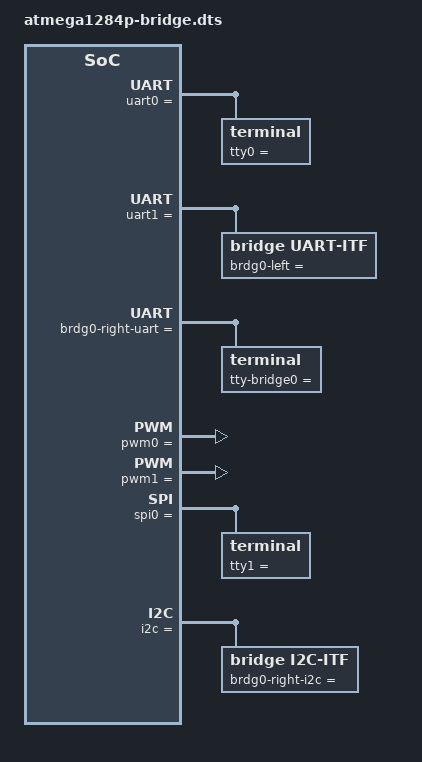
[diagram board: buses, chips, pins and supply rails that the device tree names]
/**
 * Copyright (C) 2022 Jan Nowotsch
 * Author Jan Nowotsch	<jan.nowotsch@gmail.com>
 *
 * Released under the terms of the GNU GPL v2.0
 */



memory = {
	flash = {
		baseaddr = 0x0;
		size = 131072;

		kernel-flash = {
			baseaddr = 0x0;
			size = 49152;
		};

		app-flash = {
			baseaddr = 0x0000c000;
			size = 81920;
		};
	};

	ram = {
		baseaddr = 0x00800000;
		size = 16640;

		registers = {
			baseaddr = 0x00800000;
			size = 256;
		};

		kernel-data = {
			baseaddr = 0x00800100;
			size = 4864;
		};

		kernel-heap = {
			baseaddr = 0x00801400;
			size = 2560;
		};

		kernel-stack = {
			baseaddr = 0x00801e00;
			size = 768;
		};

		app-heap = {
			baseaddr = 0x00802100;
			size = 2560;
		};

		app-data = {
			baseaddr = 0x00802b00;
			size = 5632;
		};
	};
};

devices = {
	uart0 = {
		compatible = "avr,uart";

		/**
		 * uart hardware description
		 * 	has to match the device tree data type
		 *	of the avr uart driver
		 */
		baseaddr = 0xc0;			// uart0 config register base

		reg = [ 0x64 ];				// PRR0
		int<8> = [ 0x2 ];			// PRR0_PRUSART0

		int<8> = [
			20,						// uart0 rx interrupt
			22						// uart0 tx interrupt
		];

		tty0 = {
			compatible = "terminal";

			/**
			 * terminal configuration
			 * 	has to match the configuration data type of
			 * 	the underlying device driver
			 */
			int<32> = [ 115200 ];	// baudrate
			int<8> = [
				1,					// stop bits (1)
				0,					// parity (TPARITY_NONE)
				3,					// csize (TCS_8)
				0x0,				// iflags (none)
				0x2,				// oflags (TOFL_NLCR)
				0x0					// lflags (none)
			];

			klog = {
				compatible = "kernel,log";
			};
		};
	};

	uart1 = {
		compatible = "avr,uart";

		/**
		 * uart hardware description
		 * 	has to match the device tree data type
		 *	of the avr uart driver
		 */
		baseaddr = 0xc8;			// uart1 config register base

		reg = [ 0x64 ];				// PRR0
		int<8> = [ 0x10 ];			// PRR0_PRUSART1

		int<8> = [
			28,						// uart1 rx interrupt
			30						// uart1 tx interrupt (disabled)
		];

		brdg0-left = {
			compatible = "bridge,uart-itf";

			/* bridge config */
			int<8> = [
				0,					// id
				2,					// chunksize
				0,					// rx interrupt
				0					// tx interrupt
			];

			/* terminal config */
			int<32> = [ 115200 ];	// baudrate
			int<8> = [
				1,					// stop bits (1)
				0,					// parity (TPARITY_NONE)
				3,					// csize (TCS_8)
				0x0,				// iflags (none)
				0x0,				// oflags (none)
				0x0					// lflags (none)
			];
		};
	};

	brdg0-right-uart = {
		compatible = "bridge,uart-dev";

		/**
		 * bridge hardware description
		 *	has to match bridge_cfg_t
		 */
		/* bridge config */
		int<8> = [
			0,					// id
			2,					// chunksize
			37,					// rx interrupt
			38					// tx interrupt
		];

		tty-bridge0 = {
			compatible = "terminal";

			/**
			 * terminal configuration
			 * 	has to match the configuration data type of
			 * 	the underlying device driver uart_cfg_t
			 */
			int<32> = [ 115200 ];	// baudrate
			int<8> = [
				1,					// stop bits (1)
				0,					// parity (TPARITY_NONE)
				3,					// csize (TCS_8)
				0x0,				// iflags (none)
				0x0,				// oflags (none)
				0x0					// lflags (none)
			];
		};
	};

	eeprom0 = {
		compatible = "avr,eeprom";

		/**
		 * eeprom hardware description
		 * 	has to match the device tree data type
		 *	of the avr eeprom driver
		 */
		baseaddr = 0x3f;			// eeprom register base

		int<16> = [
			0x0,					// base address
			4096					// size
		];

		int<8> = [ 25 ];			// eeprom ready interrupt
	};

	pwm0 = {
		compatible = "avr,pwm8";

		/**
		 * pwm hardware description
		 * 	has to match the device tree data type
		 *	of the avr pwm driver
		 */
		baseaddr = 0x44;			// tcc0 config register base

		reg = [
			0x35,					// TIFR0
			0x6e					// TIMSK0
		];

		reg = [ 0x64 ];				// PRR0
		int<8> = [ 0x20 ];			// PRR0_PRTIM0

		reg = [ 0x24 ];				// DDRB
		int<8> = [ 0x18 ];			// DDRB bits 3..4

	};

	pwm1 = {
		compatible = "avr,pwm16";

		/**
		 * pwm hardware description
		 * 	has to match the device tree data type
		 *	of the avr pwm driver
		 */
		baseaddr = 0x80;			// tcc1 config register base

		reg = [
			0x36,					// TIFR1
			0x6f					// TIMSK1
		];

		reg = [ 0x64 ];				// PRR0
		int<8> = [ 0x08 ];			// PRR0_PRTIM1

		reg = [ 0x2a ];				// DDRD
		int<8> = [ 0x30 ];			// DDRD bits 4..5

	};

	pa0 = {
		compatible = "avr,gpio";

		/**
		 * gpio hardware description
		 * 	has to match the device tree data type
		 *	of the avr gpio driver
		 */
		baseaddr = 0x20;			// porta

		reg = [
			0x0,					// PCICR
			0x0						// PCMASK
		];

		int<8> = [ 0 ];				// pcint number

		int<8> = [
			0x3,					// direction (in)
			0x1						// pin mask
		];
	};

	pa1 = {
		compatible = "avr,gpio";

		/**
		 * gpio hardware description
		 * 	has to match the device tree data type
		 *	of the avr gpio driver
		 */
		baseaddr = 0x20;			// porta

		reg = [
			0x0,					// PCICR
			0x0						// PCMSK
		];

		int<8> = [ 0 ] ;			// pcint number

		int<8> = [
			0x3,					// direction (in/out)
			0x2						// pin mask
		];
	};

	int0 = {
		compatible = "avr,gpio";

		/**
		 * gpio hardware description
		 * 	has to match the device tree data type
		 *	of the avr gpio driver
		 */
		baseaddr = 0x20;			// porta

		reg = [
			0x68,					// PCICR
			0x6b					// PCMSK
		];

		int<8> = [ 2 ];				// pcint number

		int<8> = [
			0x3,					// direction (in/out)
			0x4						// pin mask
		];
	};

	spi0 = {
		compatible = "avr,spi";

		/**
		 * spi hardware description
		 * 	has to match the device tree data type
		 *	of the avr spi driver
		 */
		baseaddr = 0x4c;			// spi config register base

		reg = [ 0x24 ];				// DDRB
		int<8> = [
			0x40,					// PB6 (MISO)
			0x20,					// PB5 (MOSI)
			0x80					// PB7 (SCK)
		];

		reg = [ 0x64 ];				// PRRO
		int<8> = [ 0x4 ];			// PRR0_PRSPI

		int<8> = [ 19 ];			// interrupt number

		tty1 = {
			compatible = "terminal";

			/**
			 * serial configuration
			 * 	has to match the configuration data type of
			 * 	the underlying device driver
			 */
			int<8> = [
				1,					// device mode (master)
				0,					// sample mode (CPOL = 0, CPHA = 0)
				0,					// data order (MSB first)
				1,					// prescaler (4)
				0,					// iflags (none)
				0,					// oflags (none)
				0					// lflags (none)
			];
		};
	};

	i2c = {
		compatible = "avr,i2c";

		/**
		 * i2c hardware description
		 * 	has to match the device tree data type
		 *	of the avr i2c driver
		 */
		baseaddr = 0xb8;

		reg = [ 0x64 ];				// PRRO
		int<8> = [ 0x80 ];			// PRR0_PRTWI

		/**
		 * i2c configuration
		 *	has to match the configuration data type of
		 *	the underlying device driver
		 */
		int<8> = [ 1 ];			// mode (master)
		int<16> = [ 100 ];		// clock (100kHz)
		int<8> = [
		   1,					// broadcast (enabled)
		   1,					// address
		   0					// interrupt number
		];

		brdg0-right-i2c = {
			compatible = "bridge,i2c-itf";

			/**
			 * bridge hardware description
			 *	has to match bridge_cfg_t
			 */
			/* bridge config */
			int<8> = [
				0,					// id
				2,					// chunksize
				37,					// rx interrupt
				38					// tx interrupt
			];
		};
	};

	loop0 = {
		compatible = "loop,term";

		/**
		 * loop config
		 *	has to match loop_dt_data_t
		 */
		int<16> = [ 256 ];			// buffer size

		tty-loop0 = {
			compatible = "terminal";

			/**
			 * terminal configuration
			 *	has to match the configuration data type of
			 *	the underlying device driver, i.e. loop_cfg_t
			 */
			int<8> = [
				0x0,				// iflags (none)
				0x0,				// oflags (none)
				0x0					// lflags (none)
			];
		};
	};
};
